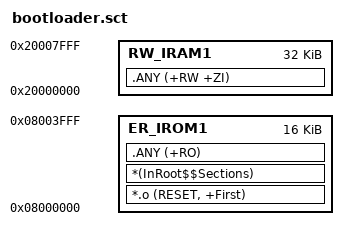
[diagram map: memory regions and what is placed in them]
; STM32F303CBT6 - 128 KiB Flash, 32 KiB SRAM
; Bootloader occupies the first 16 KiB of Flash.
; RAM is a separate load region so the linker has an explicit RW/ZI range.

LR_IROM1 0x08000000 0x00004000
{
    ER_IROM1 0x08000000 0x00004000
    {
        *.o (RESET, +First)
        *(InRoot$$Sections)
        .ANY (+RO)
    }
}

LR_IRAM1 0x20000000 0x00008000
{
    RW_IRAM1 0x20000000 0x00008000
    {
        .ANY (+RW +ZI)
    }
}
